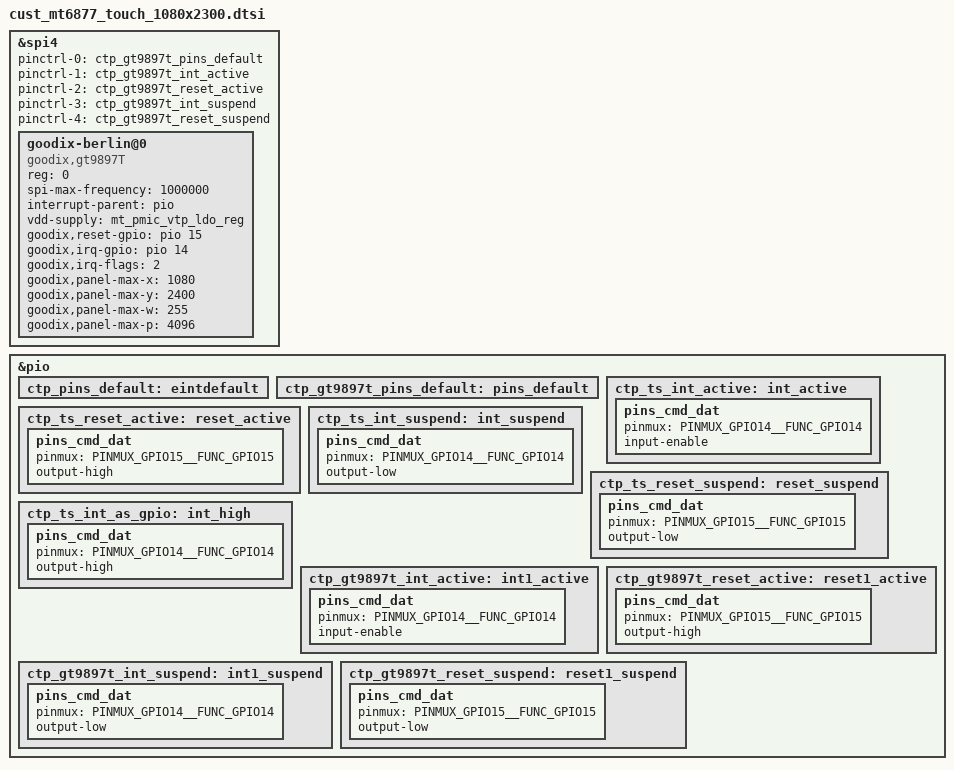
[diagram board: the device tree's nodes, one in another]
/*
 * Copyright (c) 2019 MediaTek Inc.
 * Copyright (C) 2021 XiaoMi, Inc.
 *
 * This program is free software; you can redistribute it and/or modify
 * it under the terms of the GNU General Public License version 2 as
 * published by the Free Software Foundation.
 *
 * This program is distributed in the hope that it will be useful,
 * but WITHOUT ANY WARRANTY; without even the implied warranty of
 * MERCHANTABILITY or FITNESS FOR A PARTICULAR PURPOSE.  See the
 * GNU General Public License for more details.
 */
/* TOUCH start */

/*mt_pmic_vs1_buck_reg*/
//&mt6360_ldo {
//	mt_pmic_vtp_ldo_reg: mt_pmic_vtp_ldo_reg {
//		regulator-min-microvolt = <3300000>;
//		regulator-max-microvolt = <3300000>;
//		regulator-boot-on;
//	};
//};

//&mt6359regulator {
//	touch_avdd_i2c_vreg: touch_avdd_i2c_vreg {
//		compatible = "regulator-fixed";
//		regulator-min-microvolt = <1800000>;
//		regulator-max-microvolt = <1800000>;
//		regulator-name = "touch_avdd_i2c_vreg";
//		enable-active-high;
//		gpio = <&pio 110 0>;
//	};
//};

&spi4 {
	status = "okay";
	#address-cells = <1>;
	#size-cells = <0>;
	//"gt9897t_spi_mode"
	pinctrl-names = "default", "gt9897t_int_active",
		"gt9897t_reset_active", "gt9897t_int_suspend",
		"gt9897t_reset_suspend";
	pinctrl-0 = <&ctp_gt9897t_pins_default>;
	pinctrl-1 = <&ctp_gt9897t_int_active>;
	pinctrl-2 = <&ctp_gt9897t_reset_active>;
	pinctrl-3 = <&ctp_gt9897t_int_suspend>;
	pinctrl-4 = <&ctp_gt9897t_reset_suspend>;
	//pinctrl-5 = <&ctp_gt9897t_spi_mode>;

	goodix-berlin@0 {
		status = "ok";
		compatible = "goodix,gt9897T";
		reg = <0>;
		spi-max-frequency = <1000000>;

		interrupt-parent = <&pio >;
		//goodix,avdd-name = "avdd";
		//avdd-supply = <&L7C>;
		//goodix,iovdd-name = "iovdd";
		//iovdd-supply = <&L2C>;

		vdd-supply = <&mt_pmic_vtp_ldo_reg>;//3v3
		//vcc_i2c-supply = <&touch_avdd_i2c_vreg>;//1v8

		goodix,reset-gpio = <&pio 15 0x00>;
		goodix,irq-gpio = <&pio 14 0x2800>;
		goodix,irq-flags = <2>;
		goodix,panel-max-x = <1080>;
		goodix,panel-max-y = <2400>;
		goodix,panel-max-w = <255>;
		goodix,panel-max-p = <4096>;
	};


};

&pio {
	ctp_pins_default: eintdefault {
	};
	ctp_gt9897t_pins_default: pins_default {
	};
	ctp_ts_int_active: int_active {
		pins_cmd_dat {
			pinmux = <PINMUX_GPIO14__FUNC_GPIO14>;
			input-enable;
		};
	};
	ctp_ts_reset_active: reset_active {
		pins_cmd_dat {
			pinmux = <PINMUX_GPIO15__FUNC_GPIO15>;
			output-high;
		};
	};
	ctp_ts_int_suspend: int_suspend {
		pins_cmd_dat {
			pinmux = <PINMUX_GPIO14__FUNC_GPIO14>;
			output-low;
		};
	};
	ctp_ts_reset_suspend: reset_suspend {
		pins_cmd_dat {
			pinmux = <PINMUX_GPIO15__FUNC_GPIO15>;
			output-low;
		};
	};
	//ctp_ts_i2c_mode: i2cmode_default {
	//	pins_cmd_dat {
	//		pinmux = <PINMUX_GPIO64__FUNC_SCL0>,
	//			<PINMUX_GPIO65__FUNC_SDA0>;
	//	};
	//};
	ctp_ts_int_as_gpio: int_high {
		pins_cmd_dat {
			pinmux = <PINMUX_GPIO14__FUNC_GPIO14>;
			output-high;
		};
	};
	ctp_gt9897t_int_active: int1_active {
		pins_cmd_dat {
			pinmux = <PINMUX_GPIO14__FUNC_GPIO14>;
			input-enable;
		};
	};
	ctp_gt9897t_reset_active: reset1_active {
		pins_cmd_dat {
			pinmux = <PINMUX_GPIO15__FUNC_GPIO15>;
			output-high;
		};
	};
	ctp_gt9897t_int_suspend: int1_suspend {
		pins_cmd_dat {
			pinmux = <PINMUX_GPIO14__FUNC_GPIO14>;
			output-low;
		};
	};
	ctp_gt9897t_reset_suspend: reset1_suspend {
		pins_cmd_dat {
			pinmux = <PINMUX_GPIO15__FUNC_GPIO15>;
			output-low;
		};
	};
	//ctp_gt9897t_spi_mode: spimode_default {
	//	pins_cmd_dat {
	//		pinmux = <PINMUX_GPIO12__FUNC_SPI4_MI>,
	//			<PINMUX_GPIO13__FUNC_SPI4_MO>,
	//			<PINMUX_GPIO64__FUNC_SPI4_CLK>,
	//			<PINMUX_GPIO65__FUNC_SPI4_CSB>;
	//		drive-strength = <2>;
	//	};
	//};
};
/* TOUCH end */
